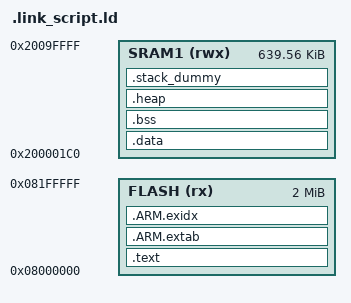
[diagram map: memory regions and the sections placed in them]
STACK_SIZE = 4096;
MEMORY
{
  FLASH (rx) : ORIGIN = 0x08000000, LENGTH = 2048K
  SRAM1 (rwx) : ORIGIN = 0x200001C0, LENGTH = 640k - 0x1C0
}
ENTRY(Reset_Handler)
SECTIONS
{
    .text :
    {
        KEEP(*(.isr_vector))
        *(.text*)
        KEEP(*(.init))
        KEEP(*(.fini))
        *crtbegin.o(.ctors)
        *crtbegin?.o(.ctors)
        *(EXCLUDE_FILE(*crtend?.o *crtend.o) .ctors)
        *(SORT(.ctors.*))
        *(.ctors)
        *crtbegin.o(.dtors)
        *crtbegin?.o(.dtors)
        *(EXCLUDE_FILE(*crtend?.o *crtend.o) .dtors)
        *(SORT(.dtors.*))
        *(.dtors)
        *(.rodata*)
        KEEP(*(.eh_frame*))
    } > FLASH
    .ARM.extab :
    {
        *(.ARM.extab* .gnu.linkonce.armextab.*)
    } > FLASH
    __exidx_start = .;
    .ARM.exidx :
    {
        *(.ARM.exidx* .gnu.linkonce.armexidx.*)
    } > FLASH
    __exidx_end = .;
    __etext = .;
    _sidata = .;
    .data : AT (__etext)
    {
        __data_start__ = .;
        _sdata = .;
        *(vtable)
        *(.data*)
        . = ALIGN(8);
        PROVIDE_HIDDEN (__preinit_array_start = .);
        KEEP(*(.preinit_array))
        PROVIDE_HIDDEN (__preinit_array_end = .);
        . = ALIGN(8);
        PROVIDE_HIDDEN (__init_array_start = .);
        KEEP(*(SORT(.init_array.*)))
        KEEP(*(.init_array))
        PROVIDE_HIDDEN (__init_array_end = .);
        . = ALIGN(8);
        PROVIDE_HIDDEN (__fini_array_start = .);
        KEEP(*(SORT(.fini_array.*)))
        KEEP(*(.fini_array))
        PROVIDE_HIDDEN (__fini_array_end = .);
        KEEP(*(.jcr*))
        . = ALIGN(8);
        __data_end__ = .;
        _edata = .;
    } > SRAM1
    .bss :
    {
        . = ALIGN(8);
        __bss_start__ = .;
        _sbss = .;
        *(.bss*)
        *(COMMON)
        . = ALIGN(8);
        __bss_end__ = .;
        _ebss = .;
    } > SRAM1
    .heap (COPY):
    {
        __end__ = .;
        end = __end__;
        *(.heap*)
        . = ORIGIN(SRAM1) + LENGTH(SRAM1) - STACK_SIZE;
        __HeapLimit = .;
    } > SRAM1
    .stack_dummy (COPY):
    {
        *(.stack*)
    } > SRAM1
    __StackTop = ORIGIN(SRAM1) + LENGTH(SRAM1);
    _estack = __StackTop;
    __StackLimit = __StackTop - STACK_SIZE;
    PROVIDE(__stack = __StackTop);
    ASSERT(__StackLimit >= __HeapLimit, "region RAM overflowed with stack")
}
